# STM32H7x5 register map
File version: 1.1
CPU: CM7 r0p0, little endian, no MPU, no FPU, 3 interrupt priority bits
Registers are 32-bit, read-write, reset 0x0 unless marked. A register's access mark holds for its fields unless they carry their own. Offsets are from the block's base; [hi:lo] are bit positions; {n}, {i} and the like mark numbered series.

## I2C1 — I2C
Base 0x40005400
Same registers: I2C2 0x40005800, I2C3 0x40005C00, I2C4 0x58001C00
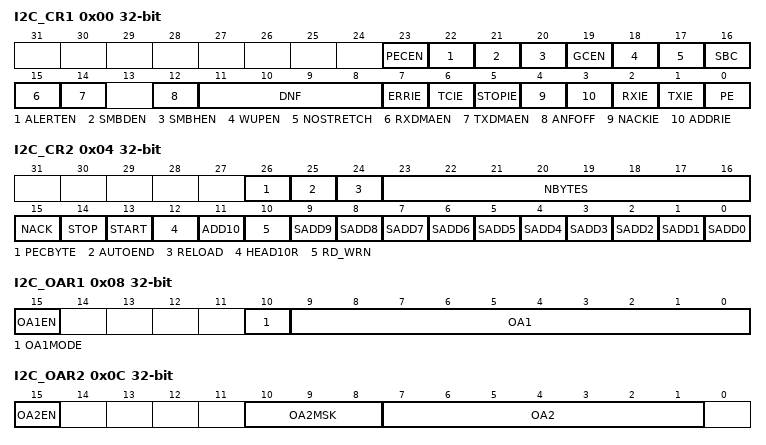
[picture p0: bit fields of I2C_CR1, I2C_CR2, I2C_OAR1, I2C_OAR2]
0x00 I2C_CR1 — Access: No wait states, except if a write access occurs while a write access to this register is ongoing. In this case, wait states are inserted in the second write access until the previous one is completed. The latency of the second write access can be up to 2 x PCLK1 + 6 x I2CCLK.
  [23] PECEN — PEC enable Note: If the SMBus feature is not supported, this bit is reserved and forced by hardware to 0. Please refer to Section25.3: I2C implementation.
  [22] ALERTEN — SMBus alert enable Device mode (SMBHEN=0): Host mode (SMBHEN=1): Note: When ALERTEN=0, the SMBA pin can be used as a standard GPIO. If the SMBus feature is not supported, this bit is reserved and forced by hardware to 0. Please refer to Section25.3: I2C implementation.
  [21] SMBDEN — SMBus Device Default address enable Note: If the SMBus feature is not supported, this bit is reserved and forced by hardware to 0. Please refer to Section25.3: I2C implementation.
  [20] SMBHEN — SMBus Host address enable Note: If the SMBus feature is not supported, this bit is reserved and forced by hardware to 0. Please refer to Section25.3: I2C implementation.
  [19] GCEN — General call enable
  [18] WUPEN — Wakeup from Stop mode enable Note: If the Wakeup from Stop mode feature is not supported, this bit is reserved and forced by hardware to 0. Please refer to Section25.3: I2C implementation. Note: WUPEN can be set only when DNF = 0000
  [17] NOSTRETCH — Clock stretching disable This bit is used to disable clock stretching in slave mode. It must be kept cleared in master mode. Note: This bit can only be programmed when the I2C is disabled (PE = 0).
  [16] SBC — Slave byte control This bit is used to enable hardware byte control in slave mode.
  [15] RXDMAEN — DMA reception requests enable
  [14] TXDMAEN — DMA transmission requests enable
  [12] ANFOFF — Analog noise filter OFF Note: This bit can only be programmed when the I2C is disabled (PE = 0).
  [11:8] DNF — Digital noise filter These bits are used to configure the digital noise filter on SDA and SCL input. The digital filter will filter spikes with a length of up to DNF[3:0] * tI2CCLK ... Note: If the analog filter is also enabled, the digital filter is added to the analog filter. This filter can only be programmed when the I2C is disabled (PE = 0).
  [7] ERRIE — Error interrupts enable Note: Any of these errors generate an interrupt: Arbitration Loss (ARLO) Bus Error detection (BERR) Overrun/Underrun (OVR) Timeout detection (TIMEOUT) PEC error detection (PECERR) Alert pin event detection (ALERT)
  [6] TCIE — Transfer Complete interrupt enable Note: Any of these events will generate an interrupt: Transfer Complete (TC) Transfer Complete Reload (TCR)
  [5] STOPIE — STOP detection Interrupt enable
  [4] NACKIE — Not acknowledge received Interrupt enable
  [3] ADDRIE — Address match Interrupt enable (slave only)
  [2] RXIE — RX Interrupt enable
  [1] TXIE — TX Interrupt enable
  [0] PE — Peripheral enable Note: When PE=0, the I2C SCL and SDA lines are released. Internal state machines and status bits are put back to their reset value. When cleared, PE must be kept low for at least 3 APB clock cycles.
0x04 I2C_CR2 — Access: No wait states, except if a write access occurs while a write access to this register is ongoing. In this case, wait states are inserted in the second write access until the previous one is completed. The latency of the second write access can be up to 2 x PCLK1 + 6 x I2CCLK.
  [26] PECBYTE — Packet error checking byte This bit is set by software, and cleared by hardware when the PEC is transferred, or when a STOP condition or an Address matched is received, also when PE=0. Note: Writing 0 to this bit has no effect. This bit has no effect when RELOAD is set. This bit has no effect is slave mode when SBC=0. If the SMBus feature is not supported, this bit is reserved and forced by hardware to 0. Please refer to Section25.3: I2C implementation.
  [25] AUTOEND — Automatic end mode (master mode) This bit is set and cleared by software. Note: This bit has no effect in slave mode or when the RELOAD bit is set.
  [24] RELOAD — NBYTES reload mode This bit is set and cleared by software.
  [23:16] NBYTES — Number of bytes The number of bytes to be transmitted/received is programmed there. This field is dont care in slave mode with SBC=0. Note: Changing these bits when the START bit is set is not allowed.
  [15] NACK — NACK generation (slave mode) The bit is set by software, cleared by hardware when the NACK is sent, or when a STOP condition or an Address matched is received, or when PE=0. Note: Writing 0 to this bit has no effect. This bit is used in slave mode only: in master receiver mode, NACK is automatically generated after last byte preceding STOP or RESTART condition, whatever the NACK bit value. When an overrun occurs in slave receiver NOSTRETCH mode, a NACK is automatically generated whatever the NACK bit value. When hardware PEC checking is enabled (PECBYTE=1), the PEC acknowledge value does not depend on the NACK value.
  [14] STOP — Stop generation (master mode) The bit is set by software, cleared by hardware when a Stop condition is detected, or when PE = 0. In Master Mode: Note: Writing 0 to this bit has no effect.
  [13] START — Start generation This bit is set by software, and cleared by hardware after the Start followed by the address sequence is sent, by an arbitration loss, by a timeout error detection, or when PE = 0. It can also be cleared by software by writing 1 to the ADDRCF bit in the I2C_ICR register. If the I2C is already in master mode with AUTOEND = 0, setting this bit generates a Repeated Start condition when RELOAD=0, after the end of the NBYTES transfer. Otherwise setting this bit will generate a START condition once the bus is free. Note: Writing 0 to this bit has no effect. The START bit can be set even if the bus is BUSY or I2C is in slave mode. This bit has no effect when RELOAD is set.
  [12] HEAD10R — 10-bit address header only read direction (master receiver mode) Note: Changing this bit when the START bit is set is not allowed.
  [11] ADD10 — 10-bit addressing mode (master mode) Note: Changing this bit when the START bit is set is not allowed.
  [10] RD_WRN — Transfer direction (master mode) Note: Changing this bit when the START bit is set is not allowed.
  [9] SADD9 — Slave address bit 9:8 (master mode) In 7-bit addressing mode (ADD10 = 0): These bits are dont care In 10-bit addressing mode (ADD10 = 1): These bits should be written with bits 9:8 of the slave address to be sent Note: Changing these bits when the START bit is set is not allowed.
  [8] SADD8 — Slave address bit 9:8 (master mode) In 7-bit addressing mode (ADD10 = 0): These bits are dont care In 10-bit addressing mode (ADD10 = 1): These bits should be written with bits 9:8 of the slave address to be sent Note: Changing these bits when the START bit is set is not allowed.
  [n] SADD{n} (n=1..7) — Slave address bit 7:1 (master mode) In 7-bit addressing mode (ADD10 = 0): These bits should be written with the 7-bit slave address to be sent In 10-bit addressing mode (ADD10 = 1): These bits should be written with bits 7:1 of the slave address to be sent. Note: Changing these bits when the START bit is set is not allowed.
  [0] SADD0 — Slave address bit 0 (master mode) In 7-bit addressing mode (ADD10 = 0): This bit is dont care In 10-bit addressing mode (ADD10 = 1): This bit should be written with bit 0 of the slave address to be sent Note: Changing these bits when the START bit is set is not allowed.
0x08 I2C_OAR1 — Access: No wait states, except if a write access occurs while a write access to this register is ongoing. In this case, wait states are inserted in the second write access until the previous one is completed. The latency of the second write access can be up to 2 x PCLK1 + 6 x I2CCLK.
  [15] OA1EN — Own Address 1 enable
  [10] OA1MODE — Own Address 1 10-bit mode Note: This bit can be written only when OA1EN=0.
  [9:0] OA1 — Interface address 7-bit addressing mode: dont care 10-bit addressing mode: bits 9:8 of address Note: These bits can be written only when OA1EN=0. OA1[7:1]: Interface address Bits 7:1 of address Note: These bits can be written only when OA1EN=0. OA1[0]: Interface address 7-bit addressing mode: dont care 10-bit addressing mode: bit 0 of address Note: This bit can be written only when OA1EN=0.
0x0C I2C_OAR2 — Access: No wait states, except if a write access occurs while a write access to this register is ongoing. In this case, wait states are inserted in the second write access until the previous one is completed. The latency of the second write access can be up to 2 x PCLK1 + 6 x I2CCLK.
  [15] OA2EN — Own Address 2 enable
  [10:8] OA2MSK — Own Address 2 masks Note: These bits can be written only when OA2EN=0. As soon as OA2MSK is not equal to 0, the reserved I2C addresses (0b0000xxx and 0b1111xxx) are not acknowledged even if the comparison matches.
  [7:1] OA2 — Interface address bits 7:1 of address Note: These bits can be written only when OA2EN=0.
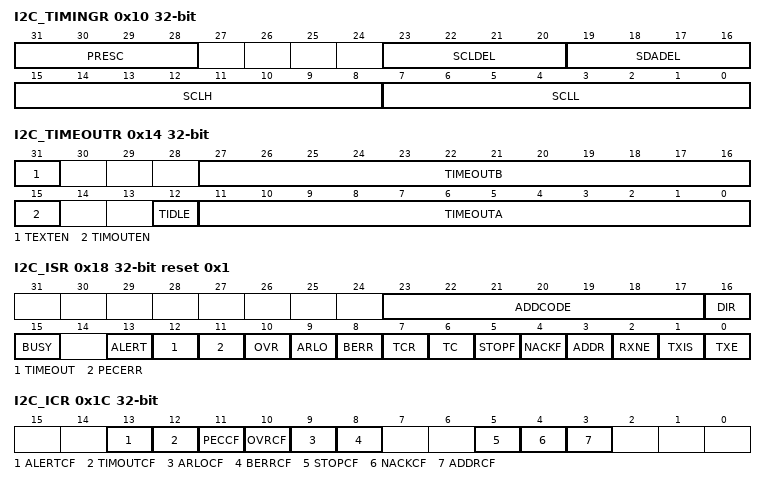
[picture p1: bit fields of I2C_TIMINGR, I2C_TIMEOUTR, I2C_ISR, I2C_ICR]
0x10 I2C_TIMINGR — Access: No wait states
  [31:28] PRESC — Timing prescaler This field is used to prescale I2CCLK in order to generate the clock period tPRESC used for data setup and hold counters (refer to I2C timings on page9) and for SCL high and low level counters (refer to I2C master initialization on page24). tPRESC = (PRESC+1) x tI2CCLK
  [23:20] SCLDEL — Data setup time This field is used to generate a delay tSCLDEL between SDA edge and SCL rising edge. In master mode and in slave mode with NOSTRETCH = 0, the SCL line is stretched low during tSCLDEL. tSCLDEL = (SCLDEL+1) x tPRESC Note: tSCLDEL is used to generate tSU:DAT timing.
  [19:16] SDADEL — Data hold time This field is used to generate the delay tSDADEL between SCL falling edge and SDA edge. In master mode and in slave mode with NOSTRETCH = 0, the SCL line is stretched low during tSDADEL. tSDADEL= SDADEL x tPRESC Note: SDADEL is used to generate tHD:DAT timing.
  [15:8] SCLH — SCL high period (master mode) This field is used to generate the SCL high period in master mode. tSCLH = (SCLH+1) x tPRESC Note: SCLH is also used to generate tSU:STO and tHD:STA timing.
  [7:0] SCLL — SCL low period (master mode) This field is used to generate the SCL low period in master mode. tSCLL = (SCLL+1) x tPRESC Note: SCLL is also used to generate tBUF and tSU:STA timings.
0x14 I2C_TIMEOUTR — Access: No wait states, except if a write access occurs while a write access to this register is ongoing. In this case, wait states are inserted in the second write access until the previous one is completed. The latency of the second write access can be up to 2 x PCLK1 + 6 x I2CCLK.
  [31] TEXTEN — Extended clock timeout enable
  [27:16] TIMEOUTB — Bus timeout B This field is used to configure the cumulative clock extension timeout: In master mode, the master cumulative clock low extend time (tLOW:MEXT) is detected In slave mode, the slave cumulative clock low extend time (tLOW:SEXT) is detected tLOW:EXT= (TIMEOUTB+1) x 2048 x tI2CCLK Note: These bits can be written only when TEXTEN=0.
  [15] TIMOUTEN — Clock timeout enable
  [12] TIDLE — Idle clock timeout detection Note: This bit can be written only when TIMOUTEN=0.
  [11:0] TIMEOUTA — Bus Timeout A This field is used to configure: The SCL low timeout condition tTIMEOUT when TIDLE=0 tTIMEOUT= (TIMEOUTA+1) x 2048 x tI2CCLK The bus idle condition (both SCL and SDA high) when TIDLE=1 tIDLE= (TIMEOUTA+1) x 4 x tI2CCLK Note: These bits can be written only when TIMOUTEN=0.
0x18 I2C_ISR access per field reset 0x1 — Access: No wait states
  [23:17] ADDCODE ro — Address match code (Slave mode) These bits are updated with the received address when an address match event occurs (ADDR = 1). In the case of a 10-bit address, ADDCODE provides the 10-bit header followed by the 2 MSBs of the address.
  [16] DIR ro — Transfer direction (Slave mode) This flag is updated when an address match event occurs (ADDR=1).
  [15] BUSY ro — Bus busy This flag indicates that a communication is in progress on the bus. It is set by hardware when a START condition is detected. It is cleared by hardware when a Stop condition is detected, or when PE=0.
  [13] ALERT ro — SMBus alert This flag is set by hardware when SMBHEN=1 (SMBus host configuration), ALERTEN=1 and a SMBALERT event (falling edge) is detected on SMBA pin. It is cleared by software by setting the ALERTCF bit. Note: This bit is cleared by hardware when PE=0. If the SMBus feature is not supported, this bit is reserved and forced by hardware to 0. Please refer to Section25.3: I2C implementation.
  [12] TIMEOUT ro — Timeout or tLOW detection flag This flag is set by hardware when a timeout or extended clock timeout occurred. It is cleared by software by setting the TIMEOUTCF bit. Note: This bit is cleared by hardware when PE=0. If the SMBus feature is not supported, this bit is reserved and forced by hardware to 0. Please refer to Section25.3: I2C implementation.
  [11] PECERR ro — PEC Error in reception This flag is set by hardware when the received PEC does not match with the PEC register content. A NACK is automatically sent after the wrong PEC reception. It is cleared by software by setting the PECCF bit. Note: This bit is cleared by hardware when PE=0. If the SMBus feature is not supported, this bit is reserved and forced by hardware to 0. Please refer to Section25.3: I2C implementation.
  [10] OVR ro — Overrun/Underrun (slave mode) This flag is set by hardware in slave mode with NOSTRETCH=1, when an overrun/underrun error occurs. It is cleared by software by setting the OVRCF bit. Note: This bit is cleared by hardware when PE=0.
  [9] ARLO ro — Arbitration lost This flag is set by hardware in case of arbitration loss. It is cleared by software by setting the ARLOCF bit. Note: This bit is cleared by hardware when PE=0.
  [8] BERR ro — Bus error This flag is set by hardware when a misplaced Start or Stop condition is detected whereas the peripheral is involved in the transfer. The flag is not set during the address phase in slave mode. It is cleared by software by setting BERRCF bit. Note: This bit is cleared by hardware when PE=0.
  [7] TCR ro — Transfer Complete Reload This flag is set by hardware when RELOAD=1 and NBYTES data have been transferred. It is cleared by software when NBYTES is written to a non-zero value. Note: This bit is cleared by hardware when PE=0. This flag is only for master mode, or for slave mode when the SBC bit is set.
  [6] TC ro — Transfer Complete (master mode) This flag is set by hardware when RELOAD=0, AUTOEND=0 and NBYTES data have been transferred. It is cleared by software when START bit or STOP bit is set. Note: This bit is cleared by hardware when PE=0.
  [5] STOPF ro — Stop detection flag This flag is set by hardware when a Stop condition is detected on the bus and the peripheral is involved in this transfer: either as a master, provided that the STOP condition is generated by the peripheral. or as a slave, provided that the peripheral has been addressed previously during this transfer. It is cleared by software by setting the STOPCF bit. Note: This bit is cleared by hardware when PE=0.
  [4] NACKF ro — Not Acknowledge received flag This flag is set by hardware when a NACK is received after a byte transmission. It is cleared by software by setting the NACKCF bit. Note: This bit is cleared by hardware when PE=0.
  [3] ADDR ro — Address matched (slave mode) This bit is set by hardware as soon as the received slave address matched with one of the enabled slave addresses. It is cleared by software by setting ADDRCF bit. Note: This bit is cleared by hardware when PE=0.
  [2] RXNE ro — Receive data register not empty (receivers) This bit is set by hardware when the received data is copied into the I2C_RXDR register, and is ready to be read. It is cleared when I2C_RXDR is read. Note: This bit is cleared by hardware when PE=0.
  [1] TXIS rw — Transmit interrupt status (transmitters) This bit is set by hardware when the I2C_TXDR register is empty and the data to be transmitted must be written in the I2C_TXDR register. It is cleared when the next data to be sent is written in the I2C_TXDR register. This bit can be written to 1 by software when NOSTRETCH=1 only, in order to generate a TXIS event (interrupt if TXIE=1 or DMA request if TXDMAEN=1). Note: This bit is cleared by hardware when PE=0.
  [0] TXE rw — Transmit data register empty (transmitters) This bit is set by hardware when the I2C_TXDR register is empty. It is cleared when the next data to be sent is written in the I2C_TXDR register. This bit can be written to 1 by software in order to flush the transmit data register I2C_TXDR. Note: This bit is set by hardware when PE=0.
0x1C I2C_ICR wo — Access: No wait states
  [13] ALERTCF — Alert flag clear Writing 1 to this bit clears the ALERT flag in the I2C_ISR register. Note: If the SMBus feature is not supported, this bit is reserved and forced by hardware to 0. Please refer to Section25.3: I2C implementation.
  [12] TIMOUTCF — Timeout detection flag clear Writing 1 to this bit clears the TIMEOUT flag in the I2C_ISR register. Note: If the SMBus feature is not supported, this bit is reserved and forced by hardware to 0. Please refer to Section25.3: I2C implementation.
  [11] PECCF — PEC Error flag clear Writing 1 to this bit clears the PECERR flag in the I2C_ISR register. Note: If the SMBus feature is not supported, this bit is reserved and forced by hardware to 0. Please refer to Section25.3: I2C implementation.
  [10] OVRCF — Overrun/Underrun flag clear Writing 1 to this bit clears the OVR flag in the I2C_ISR register.
  [9] ARLOCF — Arbitration Lost flag clear Writing 1 to this bit clears the ARLO flag in the I2C_ISR register.
  [8] BERRCF — Bus error flag clear Writing 1 to this bit clears the BERRF flag in the I2C_ISR register.
  [5] STOPCF — Stop detection flag clear Writing 1 to this bit clears the STOPF flag in the I2C_ISR register.
  [4] NACKCF — Not Acknowledge flag clear Writing 1 to this bit clears the ACKF flag in I2C_ISR register.
  [3] ADDRCF — Address matched flag clear Writing 1 to this bit clears the ADDR flag in the I2C_ISR register. Writing 1 to this bit also clears the START bit in the I2C_CR2 register.
0x20 I2C_PECR ro — Access: No wait states
  [7:0] PEC — Packet error checking register This field contains the internal PEC when PECEN=1. The PEC is cleared by hardware when PE=0.
0x24 I2C_RXDR ro — Access: No wait states
  [7:0] RXDATA — 8-bit receive data Data byte received from the I2C bus.
0x28 I2C_TXDR — Access: No wait states
  [7:0] TXDATA — 8-bit transmit data Data byte to be transmitted to the I2C bus. Note: These bits can be written only when TXE=1.
